# K1921VG7T register map
Vendor: NIIET; Series: K1921VKx; File version: 1.0
CPU: CM4 r0p1, Endian.LITTLE endian, MPU, FPU
Registers are 32-bit, read-write, reset 0x0 unless marked. A register's access mark holds for its fields unless they carry their own. Offsets are from the block's base; [hi:lo] are bit positions; lines under a group give offsets from that group; {n}, {i} and the like mark numbered series; 'fields as' and 'values as' point back to an identical list.

## TMR32_0 — Timer 32-bit with PWM control registers
Base 0x50007000
Same registers: TMR32_1 0x50008000
0x00 CTRL — Timer control register
  [9] OUTEN — Output Enable
  [8] CLKSEL — Clock Source Select
    0=SysClk (Select system Clk); 1=ExtClk (Select External Clk)
  [7] DMARXSTOP — Stop Timer when RX DMA channel ends all transactions
  [6] DMATXSTOP — Stop Timer when TX DMA channel ends all transactions
  [5:4] MODE — Count mode
    0=Stop (Timer is Stopped); 1=Up (Timer count Up); 2=Multiple (Timer count is multiple Up); 3=UpDown (Timer count is multiple Up - Down)
  [2] CLR wo — Timer Clear
  [1:0] FREESOFT — Emulation mode bits - select the behavior of the time-base counter during emulation events
    0=StopAtCLK (stop timer at next CLK tact); 1=StopAtOverload (stop timer when overload); 2=NoStop (endless count)
0x04 COUNT — Current value timer register
  [31:0] VAL — Current value timer
0x08 CLKDIV — Clock divider register
  [31:0] VAL
0x0C PERIOD — Timer period register
  [31:0] VAL
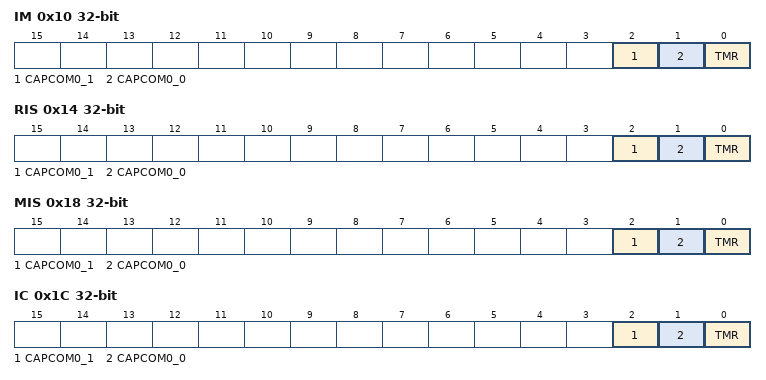
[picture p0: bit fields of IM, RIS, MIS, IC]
0x10 IM — Interrupt mask register
  [2] CAPCOM0_1 — Capcom1 Interrupt Enable
  [1] CAPCOM0_0 — Capcom0 Interrupt Enable
  [0] TMR — Timer Interrupt Enable
0x14 RIS ro — Raw Interrupt Status register
  [2] CAPCOM0_1 — Capcom1 Interrupt Status
  [1] CAPCOM0_0 — Capcom0 Interrupt Status
  [0] TMR — Timer Interrupt Status
0x18 MIS ro — Masked Interrupt Status register
  fields as RIS
0x1C IC wo — Clear Interrupt Status register
  [2] CAPCOM0_1 — Capcom1 Interrupt Clear
  [1] CAPCOM0_0 — Capcom0 Interrupt Clear
  [0] TMR — Timer Interrupt Clear
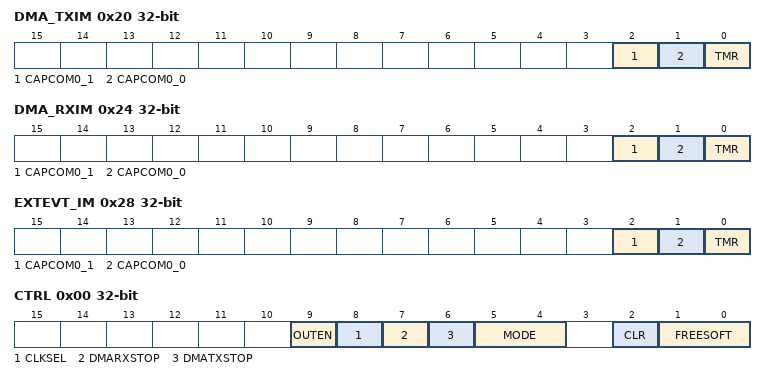
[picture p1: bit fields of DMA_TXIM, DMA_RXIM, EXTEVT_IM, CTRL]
0x20 DMA_TXIM — DMA TX request mask register
  [2] CAPCOM0_1 — Capcom1 DMA TX Request Enable
  [1] CAPCOM0_0 — Capcom0 DMA TX Request Enable
  [0] TMR — Timer DMA TX Request Enable
0x24 DMA_RXIM — DMA RX request mask register
  [2] CAPCOM0_1 — Capcom1 DMA RX Request Enable
  [1] CAPCOM0_0 — Capcom0 DMA RX Request Enable
  [0] TMR — Timer DMA RX Request Enable
0x28 EXTEVT_IM — External Event mask register
  [2] CAPCOM0_1 — Capcom1 External Event Request Enable
  [1] CAPCOM0_0 — Capcom0 External Event Request Enable
  [0] TMR — Timer External Event Request Enable
{0x100+0xC*i} CAPCOM[{i}] (i=0..1) group
  0x00 CTRL — Capture / Compare Control register
    [15:14] CAPMODE — Capture Mode
      0=NoCapture; 1=RisingEdge (Capture on rising edge); 2=FallingEdge (Capture on falling edge); 3=BothEdges (Capture on both rising and falling edges)
    [13:12] CCISEL — Capture / Compare Input Select
      0=CCIA (Capture/Compare input A); 1=CCIB (Capture/Compare input B); 2=Low (Constant 0); 3=High (Constant 1)
    [10] SCCI ro — Synchronized Capture / Compare Input
    [8] CAP — Capture Mode
      0=Compare mode; 1=Capture mode
    [7:5] OUTMODE — Output Mode
      0=Out (Out bit value); 1=Set (Set output when COUNT = CAPCOM_i.VAL); 2=ToggleReset (Toggle output when COUNT = CAPCOM_i.VAL, reset output when COUNT = CAPCOM_0.VAL); 3=SetReset (Set output when COUNT = CAPCOM_i.VAL, reset output when COUNT = CAPCOM_0.VAL); 4=Toggle output when COUNT = CAPCOM_i.VAL; 5=Reset output when COUNT = CAPCOM_i.VAL; 6=ToggleSet (Toggle output when COUNT = CAPCOM_i.VAL, set output when COUNT = CAPCOM_0.VAL); 7=ResetSet (Reset output when COUNT = CAPCOM_i.VAL, set output when COUNT = CAPCOM_0.VAL)
    [3] CCI ro — Capture / Compare Input
    [2] OUT — Output
    [1] OVF — Capture Overflow
  0x04 VAL0 — Capture/Compare Value 0 register
    [31:0] VAL
  0x08 VAL1 — Capture/Compare Value 1 register
    [31:0] VAL

## TMR16_0 — Timer 16-bit with PWM control registers
Base 0x50009000
Same registers: TMR16_1 0x5000A000, TMR16_2 0x5000B000
0x00 CTRL — Timer control register
  [9] OUTEN — CAPCOM block output enable
  [8] CLKSEL — Clock Source Select
    0=SysClk (Select system Clk); 1=ExtClk (Select External Clk)
  [7] DMARXSTOP — Stop Timer when RX DMA channel ends all transactions
  [6] DMATXSTOP — Stop Timer when TX DMA channel ends all transactions
  [5:4] MODE — Count mode
    0=Stop (Timer is Stopped); 1=Up (Timer count Up); 2=Multiple (Timer count is multiple Up); 3=UpDown (Timer count is multiple Up - Down)
  [2] CLR wo — Timer Clear
  [1:0] FREESOFT — Emulation mode bits - select the behavior of the time-base counter during emulation events
    0=StopAtCLK (stop timer at next CLK tact); 1=StopAtOverload (stop timer when overload); 2=NoStop (endless count)
0x04 COUNT — Current value timer register
  [15:0] VAL — Current value timer
0x08 CLKDIV — Clock divider register
  [15:0] VAL
0x0C PERIOD — Timer period register
  [15:0] VAL
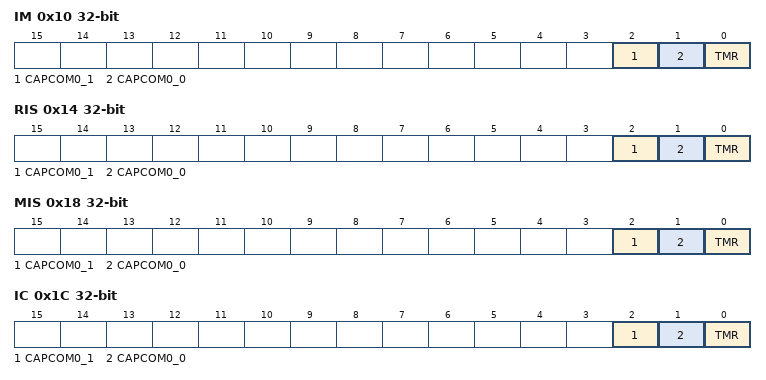
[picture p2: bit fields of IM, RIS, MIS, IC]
0x10 IM — Interrupt mask register
  [2] CAPCOM0_1 — Capcom1 Interrupt Enable
  [1] CAPCOM0_0 — Capcom0 Interrupt Enable
  [0] TMR — Timer Interrupt Enable
0x14 RIS ro — Raw Interrupt Status register
  [2] CAPCOM0_1 — Capcom1 Interrupt Status
  [1] CAPCOM0_0 — Capcom0 Interrupt Status
  [0] TMR — Timer Interrupt Status
0x18 MIS ro — Masked Interrupt Status register
  fields as RIS
0x1C IC wo — Clear Interrupt Status register
  [2] CAPCOM0_1 — Capcom1 Interrupt Clear
  [1] CAPCOM0_0 — Capcom0 Interrupt Clear
  [0] TMR — Timer Interrupt Clear
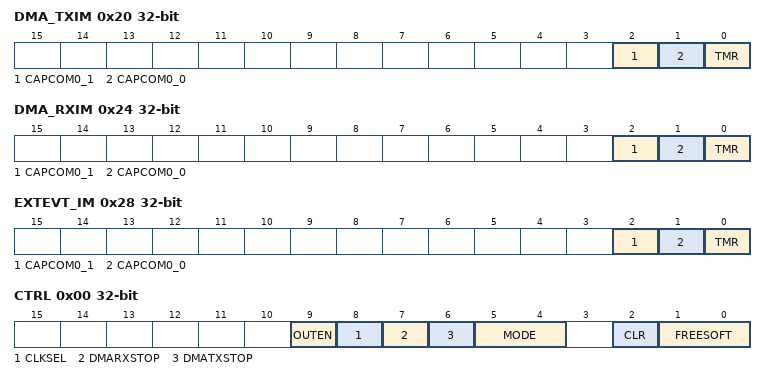
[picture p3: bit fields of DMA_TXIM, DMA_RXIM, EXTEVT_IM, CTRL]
0x20 DMA_TXIM — DMA TX request mask register
  [2] CAPCOM0_1 — Capcom1 DMA TX Request Enable
  [1] CAPCOM0_0 — Capcom0 DMA TX Request Enable
  [0] TMR — Timer DMA TX Request Enable
0x24 DMA_RXIM — DMA RX request mask register
  [2] CAPCOM0_1 — Capcom1 DMA RX Request Enable
  [1] CAPCOM0_0 — Capcom0 DMA RX Request Enable
  [0] TMR — Timer DMA RX Request Enable
0x28 EXTEVT_IM — External Event mask register
  [2] CAPCOM0_1 — Capcom1 External Event Request Enable
  [1] CAPCOM0_0 — Capcom0 External Event Request Enable
  [0] TMR — Timer External Event Request Enable
{0x100+0xC*i} CAPCOM[{i}] (i=0..1) group
  0x00 CTRL — Capture / Compare Control register
    [15:14] CAPMODE — Capture Mode
      0=NoCapture; 1=RisingEdge (Capture on rising edge); 2=FallingEdge (Capture on falling edge); 3=BothEdges (Capture on both rising and falling edges)
    [13:12] CCISEL — Capture / Compare Input Select
      0=CCIA (Capture/Compare input A); 1=CCIB (Capture/Compare input B); 2=Low (Constant 0); 3=High (Constant 1)
    [10] SCCI ro — Synchronized Capture / Compare Input
    [8] CAP — Capture Mode
      0=Compare mode; 1=Capture mode
    [7:5] OUTMODE — Output Mode
      0=Out (Out bit value); 1=Set (Set output when COUNT = CAPCOM_i.VAL); 2=ToggleReset (Toggle output when COUNT = CAPCOM_i.VAL, reset output when COUNT = CAPCOM_0.VAL); 3=SetReset (Set output when COUNT = CAPCOM_i.VAL, reset output when COUNT = CAPCOM_0.VAL); 4=Toggle output when COUNT = CAPCOM_i.VAL; 5=Reset output when COUNT = CAPCOM_i.VAL; 6=ToggleSet (Toggle output when COUNT = CAPCOM_i.VAL, set output when COUNT = CAPCOM_0.VAL); 7=ResetSet (Reset output when COUNT = CAPCOM_i.VAL, set output when COUNT = CAPCOM_0.VAL)
    [3] CCI ro — Capture / Compare Input
    [2] OUT — Output
    [1] OVF — Capture Overflow
  0x04 VAL0 — Capture/Compare Value 0 register
    [15:0] VAL
  0x08 VAL1 — Capture/Compare Value 1 register
    [15:0] VAL

## SPI0 — SPI control registers
Base 0x50010000
Same registers: SPI1 0x50011000, SPI2 0x50012000
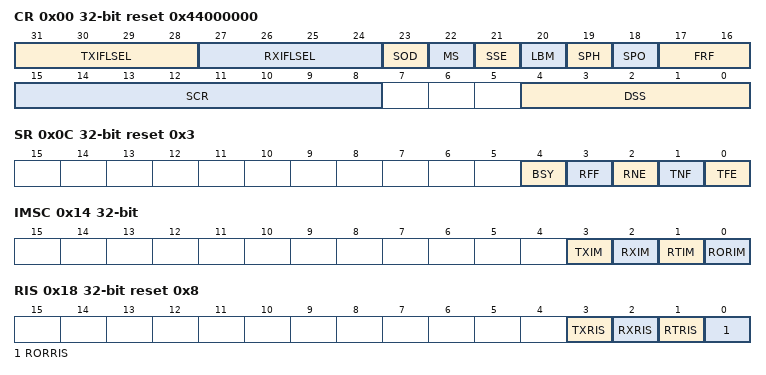
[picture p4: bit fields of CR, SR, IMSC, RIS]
0x00 CR reset 0x44000000 — Control register
  [31:28] TXIFLSEL — Transmit interrupt FIFO level select
  [27:24] RXIFLSEL — Receive interrupt FIFO level select
  [23] SOD — Disable bit data
  [22] MS — Select mode
    0=MASTER (Master mode selected); 1=SLAVE (Slave mode selected)
  [21] SSE — Enable transceiver
  [20] LBM — Test loopback mode
  [19] SPH — Phase SSPCLKOUT
  [18] SPO — Polarity SSPCLKOUT
  [17:16] FRF — Select protocol
    0=SPI (SPI of Motorola); 1=SSI (SSI of Texas Instruments); 2=Microwire of National Semiconductor
  [15:8] SCR — Value divider
  [4:0] DSS — Size of data is (value + 1) bits
    {v}={v+1}bit (data size {v+1} bits) (v=3..31)
0x08 DR — Data register
  [31:0] DATA
0x0C SR ro reset 0x3 — State register
  [4] BSY — Activity flag
  [3] RFF — Indicate full receive buffer
  [2] RNE — Indicate not empty receive buffer
  [1] TNF — Indicator the transmitter FIFO buffer is not full
  [0] TFE — FIFO buffer empty flag transmitter
0x10 CPSR — Clock division factor register
  [7:0] CPSDVSR — Clock division factor. Bit0 always 0
0x14 IMSC — Mask interrupt register
  [3] TXIM — SSPTXINTR interrupt mask bit to fill 50% or less of the FIFO buffer of the transmitter
  [2] RXIM — SSPRXINTR interrupt mask bit to fill 50% or less of the receiver FIFO buffer
  [1] RTIM — Interrupt mask bit SSPRTINTR timeout receiver
  [0] RORIM — Interrupt mask bit SSPRORINTR buffer overflow receiver
0x18 RIS ro reset 0x8 — Status register interrupt without mask
  [3] TXRIS — Interrupt status before masking SSPTXINTR
  [2] RXRIS — Interrupt status before masking SSPRXINTR
  [1] RTRIS — Interrupt status before masking SSPRTINTR
  [0] RORRIS — Interrupt status before masking SSPRORINTR
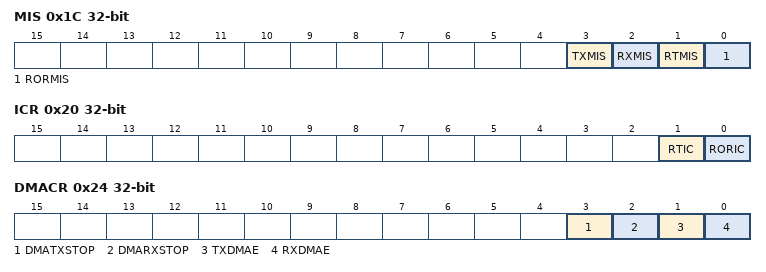
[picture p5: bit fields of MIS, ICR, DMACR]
0x1C MIS ro — Status register interrupt masking account
  [3] TXMIS — Masked interrupt status SSPTXINTR
  [2] RXMIS — Masked interrupt status SSPRXINTR
  [1] RTMIS — Masked interrupt status SSPRTINTR
  [0] RORMIS — Masked interrupt status SSPRORINTR
0x20 ICR wo — Register reset interrupt
  [1] RTIC — Reset interrupt SSPRTINTR
  [0] RORIC — Reset interrupt SSPRORINTR
0x24 DMACR — Control register DMA
  [3] DMATXSTOP — Automatic clear DMA TX request generation when channel ends all transactions
  [2] DMARXSTOP — Automatic clear DMA RX request generation when channel ends all transactions
  [1] TXDMAE — DMA enable bit transmission
  [0] RXDMAE — DMA enable bit at reception
